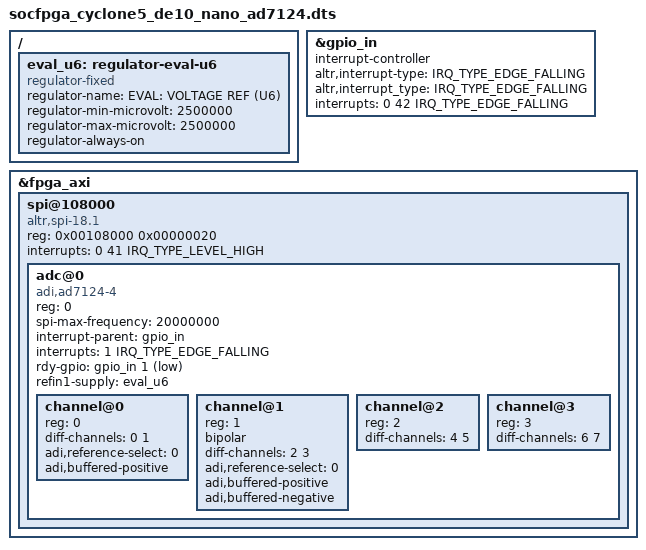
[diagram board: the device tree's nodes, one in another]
// SPDX-License-Identifier: GPL-2.0-only
/*
 * Analog Devices EVAL-AD7124-4ASDZ
 * https://www.analog.com/en/products/ad7124-4.html
 * https://analogdevicesinc.github.io/hdl/projects/ad7124_asdz/index.html
 * https://www.analog.com/en/resources/evaluation-hardware-and-software/evaluation-boards-kits/eval-ad7124-4.html
 * https://wiki.analog.com/resources/tools-software/linux-build/generic/socfpga
 *
 * hdl_project: <ad7124_asdz/de10nano>
 * board_revision: <?>
 *
 * Copyright (C) 2025 Analog Devices Inc.
 */

/dts-v1/;
#include "socfpga_cyclone5_de10_nano_hps.dtsi"
#include <dt-bindings/interrupt-controller/irq.h>
#include <dt-bindings/gpio/gpio.h>

/ {
	eval_u6: regulator-eval-u6 {
		compatible = "regulator-fixed";
		regulator-name = "EVAL: VOLTAGE REF (U6)";
		regulator-min-microvolt = <2500000>;
		regulator-max-microvolt = <2500000>;
		regulator-always-on;
	};
};

&gpio_in {
	#interrupt-cells = <2>;
	interrupt-controller;
	altr,interrupt-type = <IRQ_TYPE_EDGE_FALLING>;
	altr,interrupt_type = <IRQ_TYPE_EDGE_FALLING>;
	interrupts = <0 42 IRQ_TYPE_EDGE_FALLING>;
};

&fpga_axi {
	spi@108000 {
		compatible = "altr,spi-18.1", "altr,spi-1.0";
		reg = <0x00108000 0x00000020>;
		interrupts = <0 41 IRQ_TYPE_LEVEL_HIGH>;
		#address-cells = <1>;
		#size-cells = <0>;

		adc@0 {
			compatible = "adi,ad7124-4";
			reg = <0>;
			spi-max-frequency = <20000000>;
			interrupt-parent = <&gpio_in>;
			interrupts = <1 IRQ_TYPE_EDGE_FALLING>;
			rdy-gpio = <&gpio_in 1 GPIO_ACTIVE_LOW>;
			refin1-supply = <&eval_u6>;

			#address-cells = <1>;
			#size-cells = <0>;

			channel@0 {
				reg = <0>;
				diff-channels = <0 1>;
				adi,reference-select = <0>;
				adi,buffered-positive;
			};

			channel@1 {
				reg = <1>;
				bipolar;
				diff-channels = <2 3>;
				adi,reference-select = <0>;
				adi,buffered-positive;
				adi,buffered-negative;
			};

			channel@2 {
				reg = <2>;
				diff-channels = <4 5>;
			};

			channel@3 {
				reg = <3>;
				diff-channels = <6 7>;
			};
		};
	};
};
